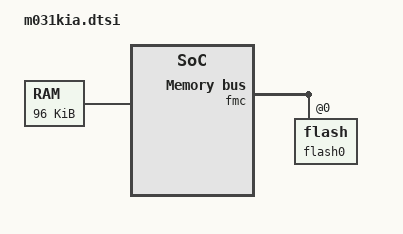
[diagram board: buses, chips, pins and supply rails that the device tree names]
/*
 * Copyright (c) 2026 Nuvoton Technology Corporation.
 *
 * SPDX-License-Identifier: Apache-2.0
 */

#include <mem.h>
#include <nuvoton/m031x.dtsi>

/ {
	sram0: memory@20000000 {
		compatible = "mmio-sram";
		reg = <0x20000000 DT_SIZE_K(96)>;
	};

	soc {
		fmc: flash-controller@4000c000 {
			#address-cells = <1>;
			#size-cells = <1>;
			ranges = <0x0 0x0 DT_SIZE_K(512)>;

			flash0: flash@0 {
				reg = <0 DT_SIZE_K(512)>;
				#address-cells = <1>;
				#size-cells = <1>;
				ranges;
			};
		};
	};
};
